AUTOSAR XML (schema 00050)
standard types defined: Boolean, uint8, uint16
package /ImplementationDataTypes
  impl type IDT_Boolean: category=VALUE, base-type=Boolean, compu {0=FALSE, 1=TRUE}
  impl type IDT_Voltage: category=VALUE, base-type=uint16, compu {phys=raw*0.1 for raw 0..200}, range raw 0..200
  impl type IDT_BatteryLevel: category=VALUE, base-type=uint8, compu {phys=raw for raw 0..100}, range raw 0..100
package /PortInterfaces
  sender receiver interface IF_BatteryVoltage  # Battery voltage, raw 0 to 200 = 0.0 to 20.0 V
    data BatteryVoltage: type=IDT_Voltage
  sender receiver interface IF_BatteryLevel  # Battery charge level in percent (0 to 100)
    data BatteryLevel: type=IDT_BatteryLevel
  sender receiver interface IF_LowBatteryStatus  # Low battery flag: 0 normal, 1 low
    data LowBattery: type=IDT_Boolean
package /SwComponentTypes
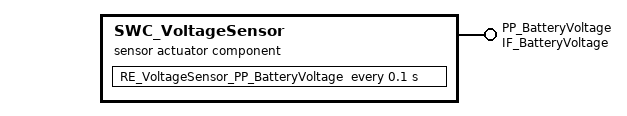
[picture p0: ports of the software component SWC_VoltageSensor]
  sensor actuator sw component type SWC_VoltageSensor  # Battery voltage sensor : publishes battery voltage (0.1 V per count)
    provide port PP_BatteryVoltage: nonqueued-sender-com-spec{data-element=BatteryVoltage, init-value=0}, provided-interface=IF_BatteryVoltage
    behavior IB_VoltageSensor
      timing event TE_RE_VoltageSensor_PP_BatteryVoltage: start-on-event=RE_VoltageSensor_PP_BatteryVoltage, period=0.1
      runnable RE_VoltageSensor_PP_BatteryVoltage
        data-send-points:
          access DSP_PP_BatteryVoltage_BatteryVoltage: accessed-variable=PP_BatteryVoltage.BatteryVoltage
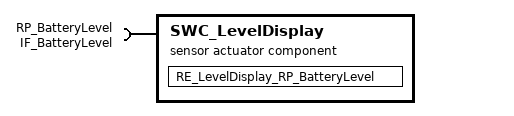
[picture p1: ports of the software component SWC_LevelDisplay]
  sensor actuator sw component type SWC_LevelDisplay  # Battery level display actuator : shows charge level in percent
    require port RP_BatteryLevel: nonqueued-receiver-com-spec{data-element=BatteryLevel, init-value=0}, required-interface=IF_BatteryLevel
    behavior IB_LevelDisplay
      data received event DRE_RE_LevelDisplay_RP_BatteryLevel: start-on-event=RE_LevelDisplay_RP_BatteryLevel, data=RP_BatteryLevel.BatteryLevel
      runnable RE_LevelDisplay_RP_BatteryLevel
        data-receive-point-by-values:
          access DRP_RP_BatteryLevel_BatteryLevel: accessed-variable=RP_BatteryLevel.BatteryLevel
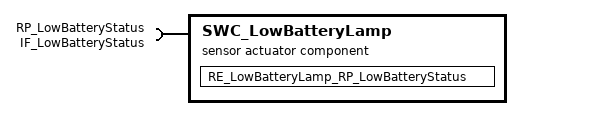
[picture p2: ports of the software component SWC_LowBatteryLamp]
  sensor actuator sw component type SWC_LowBatteryLamp  # Low battery warning lamp actuator : lights when LowBattery is TRUE
    require port RP_LowBatteryStatus: nonqueued-receiver-com-spec{data-element=LowBattery, init-value=0}, required-interface=IF_LowBatteryStatus
    behavior IB_LowBatteryLamp
      data received event DRE_RE_LowBatteryLamp_RP_LowBatteryStatus: start-on-event=RE_LowBatteryLamp_RP_LowBatteryStatus, data=RP_LowBatteryStatus.LowBattery
      runnable RE_LowBatteryLamp_RP_LowBatteryStatus
        data-receive-point-by-values:
          access DRP_RP_LowBatteryStatus_LowBattery: accessed-variable=RP_LowBatteryStatus.LowBattery
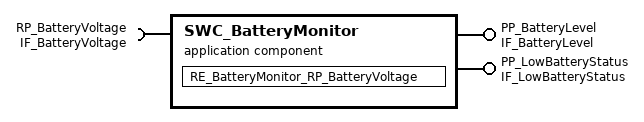
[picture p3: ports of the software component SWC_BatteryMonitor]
  application sw component type SWC_BatteryMonitor  # Battery monitor logic : converts voltage to level in percent; LowBattery = TRUE when level below 20 percent
    require port RP_BatteryVoltage: nonqueued-receiver-com-spec{data-element=BatteryVoltage, init-value=0}, required-interface=IF_BatteryVoltage
    provide port PP_BatteryLevel: nonqueued-sender-com-spec{data-element=BatteryLevel, init-value=0}, provided-interface=IF_BatteryLevel
    provide port PP_LowBatteryStatus: nonqueued-sender-com-spec{data-element=LowBattery, init-value=0}, provided-interface=IF_LowBatteryStatus
    behavior IB_BatteryMonitor
      data received event DRE_RE_BatteryMonitor_RP_BatteryVoltage: start-on-event=RE_BatteryMonitor_RP_BatteryVoltage, data=RP_BatteryVoltage.BatteryVoltage
      runnable RE_BatteryMonitor_RP_BatteryVoltage
        data-receive-point-by-values:
          access DRP_RP_BatteryVoltage_BatteryVoltage: accessed-variable=RP_BatteryVoltage.BatteryVoltage
        data-send-points:
          access DSP_PP_BatteryLevel_BatteryLevel: accessed-variable=PP_BatteryLevel.BatteryLevel
          access DSP_PP_LowBatteryStatus_LowBattery: accessed-variable=PP_LowBatteryStatus.LowBattery
package /Compositions
  composition sw component type CPT_BatteryMonitoring
    4 x component:
      BatteryMonitor: type=SWC_BatteryMonitor
      LevelDisplay: type=SWC_LevelDisplay
      LowBatteryLamp: type=SWC_LowBatteryLamp
      VoltageSensor: type=SWC_VoltageSensor
    connect VoltageSensor.PP_BatteryVoltage -> BatteryMonitor.RP_BatteryVoltage
    connect BatteryMonitor.PP_BatteryLevel -> LevelDisplay.RP_BatteryLevel
    connect BatteryMonitor.PP_LowBatteryStatus -> LowBatteryLamp.RP_LowBatteryStatus
